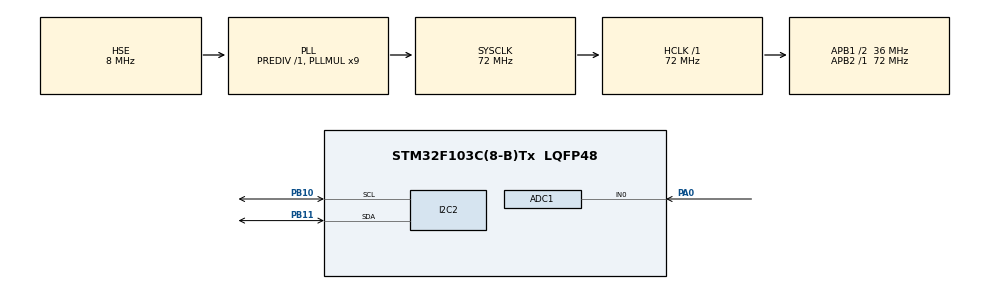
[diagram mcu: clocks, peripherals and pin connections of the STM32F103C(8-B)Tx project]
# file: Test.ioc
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Mcu.Family=STM32F1
RCC.PLLSourceVirtual=RCC_PLLSOURCE_HSE
ADC1.Rank-0\#ChannelRegularConversion=1
PD1-OSC_OUT.Mode=HSE-External-Oscillator
PB10.Mode=I2C
ADC1.ContinuousConvMode=ENABLE
PD0-OSC_IN.Signal=RCC_OSC_IN
RCC.APB1CLKDivider=RCC_HCLK_DIV2
PB11.Signal=I2C2_SDA
RCC.SYSCLKSource=RCC_SYSCLKSOURCE_PLLCLK
ProjectManager.StackSize=0x400
PA0-WKUP.Signal=ADCx_IN0
PD1-OSC_OUT.Signal=RCC_OSC_OUT
RCC.ADCPresc=RCC_ADCPCLK2_DIV6
PA13.Signal=SYS_JTMS-SWDIO
TIM1.Prescaler=72-1
PB11.Mode=I2C
ProjectManager.TargetToolchain=STM32CubeIDE
RCC.HCLKFreq_Value=72000000
RCC.APB2TimFreq_Value=72000000
RCC.USBFreq_Value=72000000
RCC.AHBFreq_Value=72000000
PD0-OSC_IN.Mode=HSE-External-Oscillator
PB10.Signal=I2C2_SCL
ADC1.Channel-0\#ChannelRegularConversion=ADC_CHANNEL_0
board=custom
RCC.PLLMUL=RCC_PLL_MUL9
RCC.APB2Freq_Value=72000000
PA14.Mode=Serial_Wire
SH.ADCx_IN0.0=ADC1_IN0,IN0
PA13.Mode=Serial_Wire
Mcu.Name=STM32F103C(8-B)Tx
VP_TIM1_VS_ClockSourceINT.Mode=Internal
ADC1.SamplingTime-0\#ChannelRegularConversion=ADC_SAMPLETIME_1CYCLE_5
RCC.SYSCLKFreq_VALUE=72000000
Mcu.Package=LQFP48
ADC1.master=1
PA14.Signal=SYS_JTCK-SWCLK
ProjectManager.HeapSize=0x200
NVIC.PriorityGroup=NVIC_PRIORITYGROUP_4
ADC1.NbrOfConversionFlag=1
RCC.APB1TimFreq_Value=72000000
TIM1.Period=0xffff-1
RCC.APB1Freq_Value=36000000

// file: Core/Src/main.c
/* USER CODE BEGIN Header */
/**
  ******************************************************************************
  * @file           : main.c
  * @brief          : Main program body
  ******************************************************************************
  * @attention
  *
  * <h2><center>&copy; Copyright (c) 2021 STMicroelectronics.
  * All rights reserved.</center></h2>
  *
  * This software component is licensed by ST under BSD 3-Clause license,
  * the "License"; You may not use this file except in compliance with the
  * License. You may obtain a copy of the License at:
  *                        opensource.org/licenses/BSD-3-Clause
  *
  ******************************************************************************
  */
/* USER CODE END Header */
#include "main.h"

/* USER CODE BEGIN Includes */
#include "supFunction.h"
#include "stdio.h"
#include "i2c&lcd.h"
#include "BH1750.h"
#include "SHT31.h"
/* USER CODE END Includes */

ADC_HandleTypeDef hadc1;

I2C_HandleTypeDef hi2c2;

TIM_HandleTypeDef htim1;

void SystemClock_Config(void);
static void MX_GPIO_Init(void);
static void MX_TIM1_Init(void);
static void MX_ADC1_Init(void);
static void MX_I2C2_Init(void);

/* USER CODE BEGIN 0 */
uint16_t soil_moisture;
float fsoil_moisture;
float lux= 0;
//uint16_t value_up[4];

/* USER CODE END 0 */

int main(void)
{

  /* MCU Configuration--------------------------------------------------------*/

  /* Reset of all peripherals, Initializes the Flash interface and the Systick. */
  HAL_Init();

  /* Configure the system clock */
  SystemClock_Config();

  /* Initialize all configured peripherals */
  MX_GPIO_Init();
  MX_TIM1_Init();
  MX_ADC1_Init();
  MX_I2C2_Init();
  /* USER CODE BEGIN 2 */
  HAL_TIM_Base_Start(&htim1);

  lcd_init();
  lcd_send_string("Four variables");

  //set up for BH1750FVI
  PowerDown();
  PowerOn();
  setMeasurement(CONT_H_MODE);

  HAL_Delay(1000);
  lcd_clear();

  /* USER CODE END 2 */

  /* Infinite loop */
  while (1)
  {

    /* USER CODE BEGIN 3 */
	  get_temp_humi();
//	  Display_LCD("Temp",1, (float)SHT31.Temperature);
//	  Display_LCD("Humi",2, (float)SHT31.Humidity);

	  char str[16];
	  lcd_put_cur(0,0);
	  sprintf(str,"T:%.2f,H:%.2f", SHT31.Temperature, SHT31.Humidity);
	  lcd_send_string(str);

//	  PowerOn();
//	  BH1750_reset();
//	  setMeasurement(ONCE_H_MODE);
	  lux = BH1750_getResult();

	  HAL_ADC_Start(&hadc1);
	  HAL_ADC_PollForConversion(&hadc1, 100);
	  soil_moisture = HAL_ADC_GetValue(&hadc1);
	  HAL_ADC_Stop(&hadc1);

	  //mapping analog signal to %
	  fsoil_moisture = 100 - mapping((float)soil_moisture, 0, 4096, 0, 100);
//	  Display_LCD("%", 2, fsoil_moisture);

	  char str1[16];
	  lcd_put_cur(1,0);
	  sprintf(str1,"S:%.2f,L:%f", fsoil_moisture, lux);
	  lcd_send_string(str1);

	  HAL_Delay(1000);
  }

  /* USER CODE END 3 */
}

void SystemClock_Config(void)
{
  RCC_OscInitTypeDef RCC_OscInitStruct = {0};
  RCC_ClkInitTypeDef RCC_ClkInitStruct = {0};
  RCC_PeriphCLKInitTypeDef PeriphClkInit = {0};

  /** Initializes the RCC Oscillators according to the specified parameters
  * in the RCC_OscInitTypeDef structure.
  */
  RCC_OscInitStruct.OscillatorType = RCC_OSCILLATORTYPE_HSE;
  RCC_OscInitStruct.HSEState = RCC_HSE_ON;
  RCC_OscInitStruct.HSEPredivValue = RCC_HSE_PREDIV_DIV1;
  RCC_OscInitStruct.HSIState = RCC_HSI_ON;
  RCC_OscInitStruct.PLL.PLLState = RCC_PLL_ON;
  RCC_OscInitStruct.PLL.PLLSource = RCC_PLLSOURCE_HSE;
  RCC_OscInitStruct.PLL.PLLMUL = RCC_PLL_MUL9;
  if (HAL_RCC_OscConfig(&RCC_OscInitStruct) != HAL_OK)
  {
    Error_Handler();
  }
  /** Initializes the CPU, AHB and APB buses clocks
  */
  RCC_ClkInitStruct.ClockType = RCC_CLOCKTYPE_HCLK|RCC_CLOCKTYPE_SYSCLK
                              |RCC_CLOCKTYPE_PCLK1|RCC_CLOCKTYPE_PCLK2;
  RCC_ClkInitStruct.SYSCLKSource = RCC_SYSCLKSOURCE_PLLCLK;
  RCC_ClkInitStruct.AHBCLKDivider = RCC_SYSCLK_DIV1;
  RCC_ClkInitStruct.APB1CLKDivider = RCC_HCLK_DIV2;
  RCC_ClkInitStruct.APB2CLKDivider = RCC_HCLK_DIV1;

  if (HAL_RCC_ClockConfig(&RCC_ClkInitStruct, FLASH_LATENCY_2) != HAL_OK)
  {
    Error_Handler();
  }
  PeriphClkInit.PeriphClockSelection = RCC_PERIPHCLK_ADC;
  PeriphClkInit.AdcClockSelection = RCC_ADCPCLK2_DIV6;
  if (HAL_RCCEx_PeriphCLKConfig(&PeriphClkInit) != HAL_OK)
  {
    Error_Handler();
  }
}

static void MX_ADC1_Init(void)
{

  ADC_ChannelConfTypeDef sConfig = {0};

  /** Common config
  */
  hadc1.Instance = ADC1;
  hadc1.Init.ScanConvMode = ADC_SCAN_DISABLE;
  hadc1.Init.ContinuousConvMode = ENABLE;
  hadc1.Init.DiscontinuousConvMode = DISABLE;
  hadc1.Init.ExternalTrigConv = ADC_SOFTWARE_START;
  hadc1.Init.DataAlign = ADC_DATAALIGN_RIGHT;
  hadc1.Init.NbrOfConversion = 1;
  if (HAL_ADC_Init(&hadc1) != HAL_OK)
  {
    Error_Handler();
  }
  /** Configure Regular Channel
  */
  sConfig.Channel = ADC_CHANNEL_0;
  sConfig.Rank = ADC_REGULAR_RANK_1;
  sConfig.SamplingTime = ADC_SAMPLETIME_1CYCLE_5;
  if (HAL_ADC_ConfigChannel(&hadc1, &sConfig) != HAL_OK)
  {
    Error_Handler();
  }

}

static void MX_I2C2_Init(void)
{

  hi2c2.Instance = I2C2;
  hi2c2.Init.ClockSpeed = 100000;
  hi2c2.Init.DutyCycle = I2C_DUTYCYCLE_2;
  hi2c2.Init.OwnAddress1 = 0;
  hi2c2.Init.AddressingMode = I2C_ADDRESSINGMODE_7BIT;
  hi2c2.Init.DualAddressMode = I2C_DUALADDRESS_DISABLE;
  hi2c2.Init.OwnAddress2 = 0;
  hi2c2.Init.GeneralCallMode = I2C_GENERALCALL_DISABLE;
  hi2c2.Init.NoStretchMode = I2C_NOSTRETCH_DISABLE;
  if (HAL_I2C_Init(&hi2c2) != HAL_OK)
  {
    Error_Handler();
  }

}

static void MX_TIM1_Init(void)
{

  TIM_ClockConfigTypeDef sClockSourceConfig = {0};
  TIM_MasterConfigTypeDef sMasterConfig = {0};

  htim1.Instance = TIM1;
  htim1.Init.Prescaler = 72-1;
  htim1.Init.CounterMode = TIM_COUNTERMODE_UP;
  htim1.Init.Period = 0xffff-1;
  htim1.Init.ClockDivision = TIM_CLOCKDIVISION_DIV1;
  htim1.Init.RepetitionCounter = 0;
  htim1.Init.AutoReloadPreload = TIM_AUTORELOAD_PRELOAD_DISABLE;
  if (HAL_TIM_Base_Init(&htim1) != HAL_OK)
  {
    Error_Handler();
  }
  sClockSourceConfig.ClockSource = TIM_CLOCKSOURCE_INTERNAL;
  if (HAL_TIM_ConfigClockSource(&htim1, &sClockSourceConfig) != HAL_OK)
  {
    Error_Handler();
  }
  sMasterConfig.MasterOutputTrigger = TIM_TRGO_RESET;
  sMasterConfig.MasterSlaveMode = TIM_MASTERSLAVEMODE_DISABLE;
  if (HAL_TIMEx_MasterConfigSynchronization(&htim1, &sMasterConfig) != HAL_OK)
  {
    Error_Handler();
  }

}

static void MX_GPIO_Init(void)
{

  /* GPIO Ports Clock Enable */
  __HAL_RCC_GPIOD_CLK_ENABLE();
  __HAL_RCC_GPIOA_CLK_ENABLE();
  __HAL_RCC_GPIOB_CLK_ENABLE();

}

void Error_Handler(void)
{
  __disable_irq();
  while (1)
  {
  }
}

/************************ (C) COPYRIGHT STMicroelectronics *****END OF FILE****/
